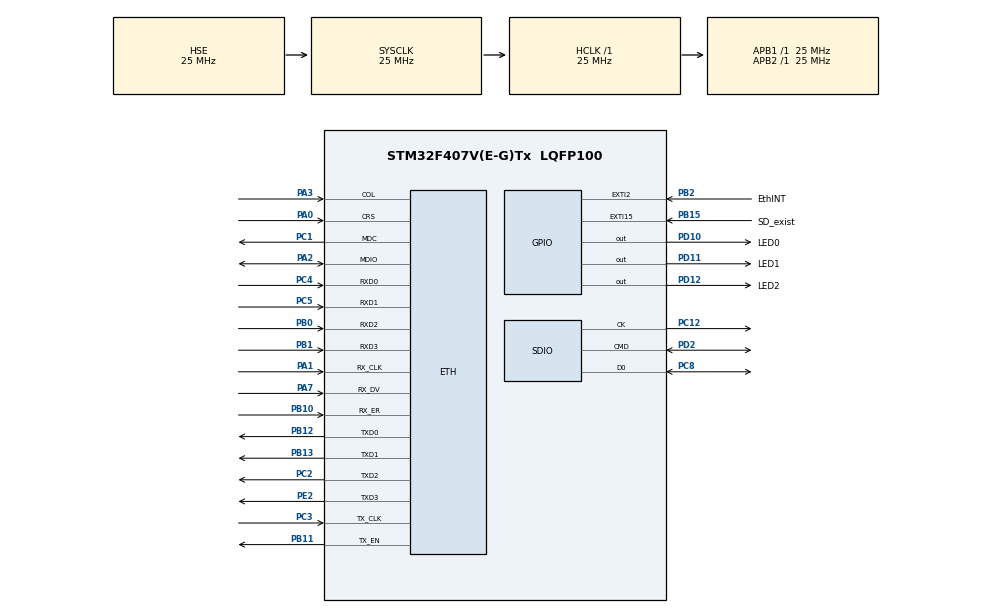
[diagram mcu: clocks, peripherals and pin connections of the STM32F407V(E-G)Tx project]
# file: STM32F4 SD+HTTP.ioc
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ETH.MediaInterface=ETH_MEDIA_INTERFACE_MII
FATFS._MAX_SS=4096
FATFS._USE_LFN=1
LWIP.LWIP_HTTPD=1
LWIP.LWIP_HTTPD_CGI=1
LWIP.LWIP_HTTPD_SSI=1
LWIP.MEMP_NUM_TCP_SEG=24
LWIP.TCP_MSS=460
LWIP.TCP_SND_BUF=1840
LWIP.TCP_WND=2048
LWIP.Version=v2.0.3_Cube
Mcu.Family=STM32F4
Mcu.Name=STM32F407V(E-G)Tx
Mcu.Package=LQFP100
NVIC.EXTI15_10_IRQn=true\:0\:0\:false\:false\:true\:true
NVIC.EXTI2_IRQn=true\:0\:0\:false\:false\:true\:true
NVIC.PriorityGroup=NVIC_PRIORITYGROUP_4
PA0-WKUP.Mode=MII
PA0-WKUP.Signal=ETH_CRS
PA1.Mode=MII
PA1.Signal=ETH_RX_CLK
PA13.Mode=Serial_Wire
PA13.Signal=SYS_JTMS-SWDIO
PA14.Mode=Serial_Wire
PA14.Signal=SYS_JTCK-SWCLK
PA2.Mode=MII
PA2.Signal=ETH_MDIO
PA3.Mode=MII
PA3.Signal=ETH_COL
PA7.Mode=MII
PA7.Signal=ETH_RX_DV
PB0.Mode=MII
PB0.Signal=ETH_RXD2
PB1.Mode=MII
PB1.Signal=ETH_RXD3
PB10.Mode=Activate Rx Err signal
PB10.Signal=ETH_RX_ER
PB11.Mode=MII
PB11.Signal=ETH_TX_EN
PB12.Mode=MII
PB12.Signal=ETH_TXD0
PB13.Mode=MII
PB13.Signal=ETH_TXD1
PB15.GPIO_Label=SD_exist
PB15.GPIO_ModeDefaultEXTI=GPIO_MODE_IT_RISING_FALLING
PB15.Signal=GPXTI15
PB2.GPIO_Label=EthINT
PB2.GPIO_ModeDefaultEXTI=GPIO_MODE_IT_RISING_FALLING
PB2.Signal=GPXTI2
PC1.Mode=MII
PC1.Signal=ETH_MDC
PC12.Mode=SD_1_bit
PC12.Signal=SDIO_CK
PC14-OSC32_IN.Mode=LSE-External-Oscillator
PC14-OSC32_IN.Signal=RCC_OSC32_IN
PC15-OSC32_OUT.Mode=LSE-External-Oscillator
PC15-OSC32_OUT.Signal=RCC_OSC32_OUT
PC2.Mode=MII
PC2.Signal=ETH_TXD2
PC3.Mode=MII
PC3.Signal=ETH_TX_CLK
PC4.Mode=MII
PC4.Signal=ETH_RXD0
PC5.Mode=MII
PC5.Signal=ETH_RXD1
PC8.GPIO_PuPd=GPIO_NOPULL
PC8.Mode=SD_1_bit
PC8.Signal=SDIO_D0
PD10.GPIO_Label=LED0
PD10.Signal=GPIO_Output
PD11.GPIO_Label=LED1
PD11.Signal=GPIO_Output
PD12.GPIO_Label=LED2
PD12.Signal=GPIO_Output
PD2.GPIO_PuPd=GPIO_NOPULL
PD2.Mode=SD_1_bit
PD2.Signal=SDIO_CMD
PE2.Mode=MII
PE2.Signal=ETH_TXD3
PH0-OSC_IN.Mode=HSE-External-Oscillator
PH0-OSC_IN.Signal=RCC_OSC_IN
PH1-OSC_OUT.Mode=HSE-External-Oscillator
PH1-OSC_OUT.Signal=RCC_OSC_OUT
ProjectManager.HeapSize=0x2000
ProjectManager.StackSize=0x4000
ProjectManager.TargetToolchain=MDK-ARM V5
RCC.48MHZClocksFreq_Value=48000000
RCC.AHBFreq_Value=25000000
RCC.APB1Freq_Value=25000000
RCC.APB1TimFreq_Value=25000000
RCC.APB2Freq_Value=25000000
RCC.APB2TimFreq_Value=25000000
RCC.CortexFreq_Value=25000000
RCC.HCLKFreq_Value=25000000
RCC.HSE_VALUE=25000000
RCC.HSI_VALUE=16000000
RCC.PLLM=15
RCC.PLLN=144
RCC.PLLQ=5
RCC.PLLSourceVirtual=RCC_PLLSOURCE_HSE
RCC.SYSCLKFreq_VALUE=25000000
RCC.SYSCLKSource=RCC_SYSCLKSOURCE_HSE
RCC.VCOOutputFreq_Value=240000000
VP_FATFS_VS_SDIO.Mode=SDIO
VP_LWIP_VS_Enabled.Mode=Enabled
board=custom

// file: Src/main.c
/**
  ******************************************************************************
  * @file           : main.c
  * @brief          : Main program body
  ******************************************************************************
  * This notice applies to any and all portions of this file
  * that are not between comment pairs USER CODE BEGIN and
  * USER CODE END. Other portions of this file, whether
  * inserted by the user or by software development tools
  * are owned by their respective copyright owners.
  *
  * Copyright (c) 2018 STMicroelectronics International N.V.
  * All rights reserved.
  *
  * Redistribution and use in source and binary forms, with or without
  * modification, are permitted, provided that the following conditions are met:
  *
  * 1. Redistribution of source code must retain the above copyright notice,
  *    this list of conditions and the following disclaimer.
  * 2. Redistributions in binary form must reproduce the above copyright notice,
  *    this list of conditions and the following disclaimer in the documentation
  *    and/or other materials provided with the distribution.
  * 3. Neither the name of STMicroelectronics nor the names of other
  *    contributors to this software may be used to endorse or promote products
  *    derived from this software without specific written permission.
  * 4. This software, including modifications and/or derivative works of this
  *    software, must execute solely and exclusively on microcontroller or
  *    microprocessor devices manufactured by or for STMicroelectronics.
  * 5. Redistribution and use of this software other than as permitted under
  *    this license is void and will automatically terminate your rights under
  *    this license.
  *
  * THIS SOFTWARE IS PROVIDED BY STMICROELECTRONICS AND CONTRIBUTORS "AS IS"
  * AND ANY EXPRESS, IMPLIED OR STATUTORY WARRANTIES, INCLUDING, BUT NOT
  * LIMITED TO, THE IMPLIED WARRANTIES OF MERCHANTABILITY, FITNESS FOR A
  * PARTICULAR PURPOSE AND NON-INFRINGEMENT OF THIRD PARTY INTELLECTUAL PROPERTY
  * RIGHTS ARE DISCLAIMED TO THE FULLEST EXTENT PERMITTED BY LAW. IN NO EVENT
  * SHALL STMICROELECTRONICS OR CONTRIBUTORS BE LIABLE FOR ANY DIRECT, INDIRECT,
  * INCIDENTAL, SPECIAL, EXEMPLARY, OR CONSEQUENTIAL DAMAGES (INCLUDING, BUT NOT
  * LIMITED TO, PROCUREMENT OF SUBSTITUTE GOODS OR SERVICES; LOSS OF USE, DATA,
  * OR PROFITS; OR BUSINESS INTERRUPTION) HOWEVER CAUSED AND ON ANY THEORY OF
  * LIABILITY, WHETHER IN CONTRACT, STRICT LIABILITY, OR TORT (INCLUDING
  * NEGLIGENCE OR OTHERWISE) ARISING IN ANY WAY OUT OF THE USE OF THIS SOFTWARE,
  * EVEN IF ADVISED OF THE POSSIBILITY OF SUCH DAMAGE.
  *
  ******************************************************************************
  */
#include "main.h"
#include "stm32f4xx_hal.h"
#include "fatfs.h"
#include "lwip.h"
#include "sdio.h"
#include "gpio.h"

/* USER CODE BEGIN Includes */
#include "net.h"
#include "app_ethernet.h"
#include "app_http.h"
/* USER CODE END Includes */

/* USER CODE BEGIN PV */
/* Private variables ---------------------------------------------------------*/
extern struct netif gnetif;
/* USER CODE END PV */

void SystemClock_Config(void);

/* USER CODE BEGIN PFP */
/* Private function prototypes -----------------------------------------------*/

/* USER CODE END PFP */

/* USER CODE BEGIN 0 */
//FATFS SDFatFs, PCFatFs;  /* File system object for SD card logical drive */
//FIL fsd, fpc;     /* File object */
//extern char SDPath[4];  /* SD logical drive path */
/* USER CODE END 0 */

int main(void)
{

  /* MCU Configuration----------------------------------------------------------*/

  /* Reset of all peripherals, Initializes the Flash interface and the Systick. */
  HAL_Init();

  /* Configure the system clock */
  SystemClock_Config();

  /* Initialize all configured peripherals */
  MX_GPIO_Init();
  MX_LWIP_Init();
  MX_SDIO_SD_Init();
  MX_FATFS_Init();
  /* USER CODE BEGIN 2 */
	//Diodes off
	HAL_GPIO_WritePin(GPIOD, GPIO_PIN_10 | GPIO_PIN_11 | GPIO_PIN_12, GPIO_PIN_SET);
	//TSP, HTTP
	tcp_server_init();
	httpd_init();
	//http RX TX
	SSI_Init();
	CGI_Init();
	//net status
	User_notification(&gnetif);
	//Make_HTTP_SDInfo();
  /* USER CODE END 2 */

  /* Infinite loop */
  /* USER CODE BEGIN WHILE */
  while (1)
  {
		ethernetif_input(&gnetif);
		sys_check_timeouts();
		DHCP_Periodic_Handle(&gnetif);
  /* USER CODE END WHILE */

  }

}

void SystemClock_Config(void)
{

  RCC_OscInitTypeDef RCC_OscInitStruct;
  RCC_ClkInitTypeDef RCC_ClkInitStruct;

    /**Configure the main internal regulator output voltage
    */
  __HAL_RCC_PWR_CLK_ENABLE();

  __HAL_PWR_VOLTAGESCALING_CONFIG(PWR_REGULATOR_VOLTAGE_SCALE1);

    /**Initializes the CPU, AHB and APB busses clocks
    */
  RCC_OscInitStruct.OscillatorType = RCC_OSCILLATORTYPE_HSE;
  RCC_OscInitStruct.HSEState = RCC_HSE_ON;
  RCC_OscInitStruct.PLL.PLLState = RCC_PLL_ON;
  RCC_OscInitStruct.PLL.PLLSource = RCC_PLLSOURCE_HSE;
  RCC_OscInitStruct.PLL.PLLM = 15;
  RCC_OscInitStruct.PLL.PLLN = 144;
  RCC_OscInitStruct.PLL.PLLP = RCC_PLLP_DIV2;
  RCC_OscInitStruct.PLL.PLLQ = 5;
  if (HAL_RCC_OscConfig(&RCC_OscInitStruct) != HAL_OK)
  {
    _Error_Handler(__FILE__, __LINE__);
  }

    /**Initializes the CPU, AHB and APB busses clocks
    */
  RCC_ClkInitStruct.ClockType = RCC_CLOCKTYPE_HCLK|RCC_CLOCKTYPE_SYSCLK
                              |RCC_CLOCKTYPE_PCLK1|RCC_CLOCKTYPE_PCLK2;
  RCC_ClkInitStruct.SYSCLKSource = RCC_SYSCLKSOURCE_HSE;
  RCC_ClkInitStruct.AHBCLKDivider = RCC_SYSCLK_DIV1;
  RCC_ClkInitStruct.APB1CLKDivider = RCC_HCLK_DIV1;
  RCC_ClkInitStruct.APB2CLKDivider = RCC_HCLK_DIV1;

  if (HAL_RCC_ClockConfig(&RCC_ClkInitStruct, FLASH_LATENCY_0) != HAL_OK)
  {
    _Error_Handler(__FILE__, __LINE__);
  }

    /**Configure the Systick interrupt time
    */
  HAL_SYSTICK_Config(HAL_RCC_GetHCLKFreq()/1000);

    /**Configure the Systick
    */
  HAL_SYSTICK_CLKSourceConfig(SYSTICK_CLKSOURCE_HCLK);

  /* SysTick_IRQn interrupt configuration */
  HAL_NVIC_SetPriority(SysTick_IRQn, 0, 0);
}

void _Error_Handler(char *file, int line)
{
  while(1)
  {
  }
}

/************************ (C) COPYRIGHT STMicroelectronics *****END OF FILE****/
